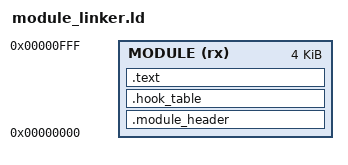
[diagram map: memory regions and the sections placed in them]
/* Module linker script - links at base 0 for slot-independent modules */
MEMORY {
    MODULE (rx) : ORIGIN = 0, LENGTH = 0x1000
}
SECTIONS {
    .module_header : {
        /* Emit 32 real bytes so objcopy keeps header padding in the raw binary. */
        LONG(0) LONG(0) LONG(0) LONG(0)
        LONG(0) LONG(0) LONG(0) LONG(0)
    } > MODULE
    .hook_table : ALIGN(4) {
        KEEP(*(.hook_table))
        . = ALIGN(4);
    } > MODULE
    .text : ALIGN(4) {
        *(.text*)
        /* .rodata is merged into .text so that PC-relative addressing
           generated by -fPIC ("LDR rX,[pc,#N]; ADD rX,pc") can reach
           string literals and other read-only data with a single
           contiguous PC offset. A separate .rodata section would
           force the compiler/linker to use a longer two-step
           sequence or risk overflowing the PC-relative range.

           Historical note: an earlier design relied on the host
           extracting R_ARM_ABS32 relocations from this section to
           rebase literal-pool absolute addresses at load time. With
           -fPIC enabled, no such relocations are emitted and no
           host-side rebasing happens (and is no longer needed). The
           merge-into-.text invariant is kept for the PC-relative
           reachability reason above. See docs/sram-module-compilation.md. */
        *(.rodata*)
        . = ALIGN(4);
    } > MODULE
    /DISCARD/ : {
        *(.data*)
        *(.bss*)
        *(.comment)
        *(.ARM.attributes)
        *(.ARM.exidx*)
        *(.ARM.extab*)
        *(.eh_frame*)
        *(.gnu.linkonce.armexidx.*)
    }
}
